# f28004x_pmbus_regs register map
Vendor: Texas Instruments
Peripheral module from a debugger description file (folder C2000).
Address unit: 16 bits
Registers are 32-bit, read-write, no defined reset value unless marked. A register's access mark holds for its fields unless they carry their own. Offsets are as the file gives them; lines under a group give offsets from that group; [hi:lo] are bit positions; {n}, {i} and the like mark numbered series; 'fields as' and 'values as' point back to an identical list; <NAME> marks a mode.

## PMBUS_REGS — PMBUS Registers
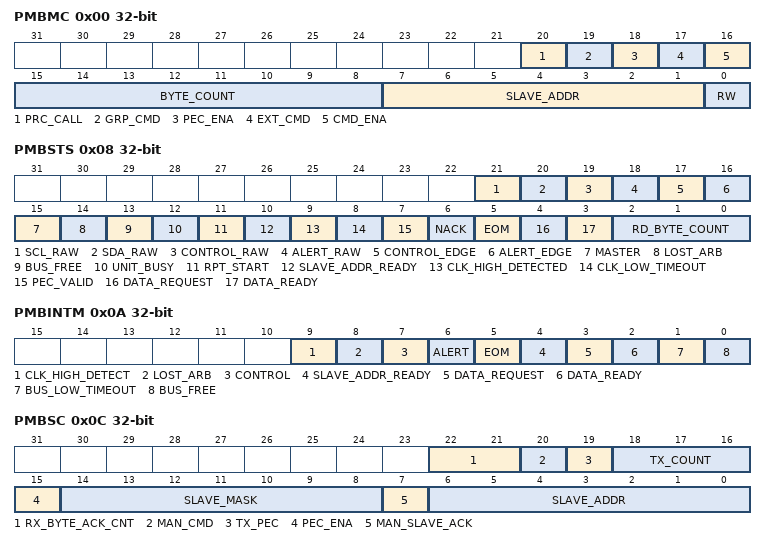
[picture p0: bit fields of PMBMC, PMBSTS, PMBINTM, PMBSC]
0x00 PMBMC — PMBUS Master Mode Control Register
  [20] PRC_CALL — Master Process Call Message Enable
  [19] GRP_CMD — Master Group Command Message Enable
  [18] PEC_ENA — Master PEC Processing Enable
  [17] EXT_CMD — Master Extended Command Code Enable
  [16] CMD_ENA — Master Command Code Enable
  [15:8] BYTE_COUNT — Number of Bytes Transmitted
  [7:1] SLAVE_ADDR — Slave Address
  [0] RW — RnW bit of the Message
0x02 PMBTXBUF — PMBUS Transmit Buffer
  [31:0] TXDATA — Transmit Message Data
0x04 PMBRXBUF ro — PMBUS Receive buffer
  [31:0] RXDATA — PMBus Receive Data Register
0x06 PMBACK — PMBUS Acknowledge Register
  [0] ACK — Allows firmware to ack/nack received data
0x08 PMBSTS access not given — PMBUS Status Register
  [21] SCL_RAW ro — PMBus Clock Pin Real Time Status
  [20] SDA_RAW ro — PMBus Data Pin Real Time Status
  [19] CONTROL_RAW ro — Control Pin Real Time Status
  [18] ALERT_RAW ro — Alert Pin Real Time Status
  [17] CONTROL_EDGE — Control Edge Detection Status (access RtoClr)
  [16] ALERT_EDGE — Alert Edge Detection Status (access RtoClr)
  [15] MASTER — Master Indicator (access RtoClr)
  [14] LOST_ARB — Lost Arbitration Flag (access RtoClr)
  [13] BUS_FREE — PMBus Free Indicator (access RtoClr)
  [12] UNIT_BUSY — PMBus Busy Indicator (access RtoClr)
  [11] RPT_START — Repeated Start Flag (access RtoClr)
  [10] SLAVE_ADDR_READY — Slave Address Ready (access RtoClr)
  [9] CLK_HIGH_DETECTED — Clock High Detection Status (access RtoClr)
  [8] CLK_LOW_TIMEOUT — Clock Low Timeout Status (access RtoClr)
  [7] PEC_VALID — PEC Valid Indicator (access RtoClr)
  [6] NACK — Not Acknowledge Flag Status (access RtoClr)
  [5] EOM — End of Message Indicator (access RtoClr)
  [4] DATA_REQUEST — Data Request Flag (access RtoClr)
  [3] DATA_READY — Data Ready Flag (access RtoClr)
  [2:0] RD_BYTE_COUNT — Number of Data Bytes available in Receive Data Register (access RtoClr)
0x0A PMBINTM — PMBUS Interrupt Mask Register
  [9] CLK_HIGH_DETECT — Clock High Detection Interrupt Mask
  [8] LOST_ARB — Lost Arbitration Interrupt Mask
  [7] CONTROL — Control Detection Interrupt Mask
  [6] ALERT — Alert Detection Interrupt Mask
  [5] EOM — End of Message Interrupt Mask
  [4] SLAVE_ADDR_READY — Slave Address Ready Interrupt Mask
  [3] DATA_REQUEST — Data Request Interrupt Mask
  [2] DATA_READY — Data Ready Interrupt Mask
  [1] BUS_LOW_TIMEOUT — Clock Low Timeout Interrupt Mask
  [0] BUS_FREE — Bus Free Interrupt Mask
0x0C PMBSC — PMBUS Slave Mode Configuration Register
  [22:21] RX_BYTE_ACK_CNT — Number of data bytes to automatically acknowledge
  [20] MAN_CMD — Manual Command Acknowledgement Mode
  [19] TX_PEC — send a PEC byte at end of message
  [18:16] TX_COUNT — Number of valid bytes in Transmit Data Register
  [15] PEC_ENA — PEC Processing Enable
  [14:8] SLAVE_MASK — Slave address mask
  [7] MAN_SLAVE_ACK — Manual Slave Address Acknowledgement Mode
  [6:0] SLAVE_ADDR — Configures the current device address of the slave.
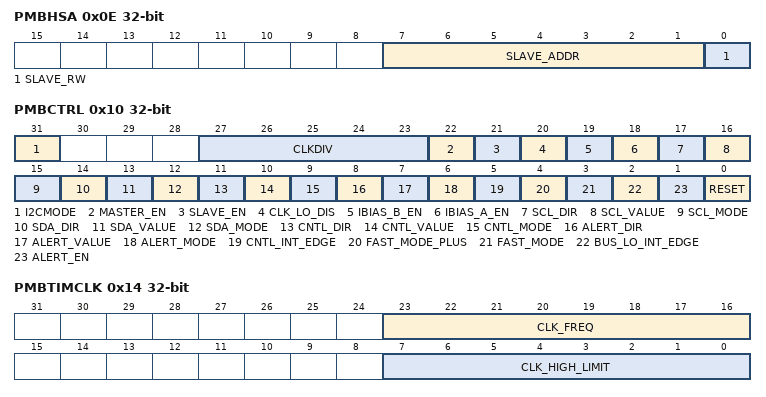
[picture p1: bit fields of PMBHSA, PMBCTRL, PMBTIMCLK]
0x0E PMBHSA ro — PMBUS Hold Slave Address Register
  [7:1] SLAVE_ADDR — Stored device address
  [0] SLAVE_RW — Stored R/W bit
0x10 PMBCTRL — PMBUS Control Register
  [31] I2CMODE — Bit to enable I2C mode
  [27:23] CLKDIV — PMBUS IP Clock Divide Value
  [22] MASTER_EN — PMBus Master Enable
  [21] SLAVE_EN — PMBus Slave Enable
  [20] CLK_LO_DIS — Clock Low Timeout Disable
  [19] IBIAS_B_EN — PMBus Current Source B Control
  [18] IBIAS_A_EN — PMBus Current Source A Control
  [17] SCL_DIR — Configures direction of PMBus clock pin in GPIO mode
  [16] SCL_VALUE — Configures output value of PMBus clock pin in GPIO Mode
  [15] SCL_MODE — Configures mode of PMBus Clock pin
  [14] SDA_DIR — Configures direction of PMBus data pin in GPIO mode
  [13] SDA_VALUE — Configures output value of PMBus data pin in GPIO Mode
  [12] SDA_MODE — Configures mode of PMBus Data pin
  [11] CNTL_DIR — Configures direction of Control pin in GPIO mode
  [10] CNTL_VALUE — Configures output value of Control pin in GPIO Mode
  [9] CNTL_MODE — Configures mode of Control pin
  [8] ALERT_DIR — Configures direction of Alert pin in GPIO mode
  [7] ALERT_VALUE — Configures output value of Alert pin in GPIO Mode
  [6] ALERT_MODE — Configures mode of Alert pin
  [5] CNTL_INT_EDGE — Control Interrupt Edge Select
  [4] FAST_MODE_PLUS — Fast Mode Plus Enable
  [3] FAST_MODE — Fast Mode Enable
  [2] BUS_LO_INT_EDGE — Clock Low Timeout Interrupt Edge Select
  [1] ALERT_EN — Slave Alert Enable
  [0] RESET — PMBus Interface Synchronous Reset
0x12 PMBTIMCTL — PMBUS Timing Control Register
  [0] TIM_OVERRIDE — Overide the default settings of the timing parameters.
0x14 PMBTIMCLK — PMBUS Clock Timing Register
  [23:16] CLK_FREQ — Determines the PMBUS master clock frequency.
  [7:0] CLK_HIGH_LIMIT — Determines the PMBUS master clock high pulse width.
0x16 PMBTIMSTSETUP — PMBUS Start Setup Time Register
  [7:0] TSU_STA — Setup time, rise edge of PMBUS master clock to start edge.
0x18 PMBTIMBIDLE — PMBUS Bus Idle Time Register
  [9:0] BUSIDLE — Determines the Bus Idle Limit
0x1A PMBTIMLOWTIMOUT — PMBUS Clock Low Timeout Value Register
  [19:0] CLKLOWTIMOUT — Determines the clock low timeout value
0x1C PMBTIMHIGHTIMOUT — PMBUS Clock High Timeout Value Register
  [9:0] CLKHIGHTIMOUT — Determines the clock high timeout value
